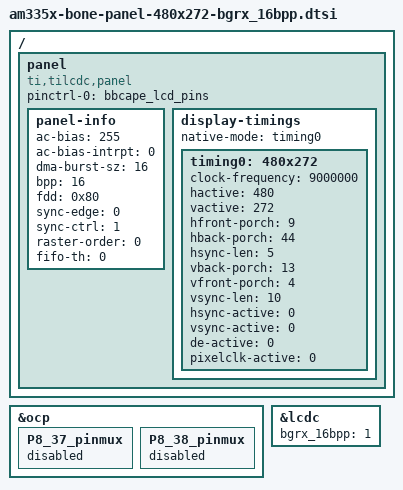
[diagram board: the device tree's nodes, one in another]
/*
 * Copyright (C) 2012 Texas Instruments Incorporated - http://www.ti.com/
 *
 * This program is free software; you can redistribute it and/or modify
 * it under the terms of the GNU General Public License version 2 as
 * published by the Free Software Foundation.
 */

&ocp {
	P8_37_pinmux {
		status = "disabled";
	};
	P8_38_pinmux {
		status = "disabled";
	};
};

&lcdc {
	bgrx_16bpp = <1>;
	status = "okay";
};

/ {
	panel {
		status = "okay";
		compatible = "ti,tilcdc,panel";
		pinctrl-names = "default";
		pinctrl-0 = <&bbcape_lcd_pins>;
		panel-info {
			ac-bias           = <255>;
			ac-bias-intrpt    = <0>;
			dma-burst-sz      = <16>;
			bpp               = <16>;
			fdd               = <0x80>;
			sync-edge         = <0>;
			sync-ctrl         = <1>;
			raster-order      = <0>;
			fifo-th           = <0>;
		};
		display-timings {
			native-mode = <&timing0>;
			timing0: 480x272 {
				clock-frequency = <9000000>;
				hactive = <480>;
				vactive = <272>;
				hfront-porch = <9>;
				hback-porch = <44>;
				hsync-len = <5>;
				vback-porch = <13>;
				vfront-porch = <4>;
				vsync-len = <10>;
				hsync-active = <0>;
				vsync-active = <0>;
				de-active = <0>;
				pixelclk-active = <0>;
			};
		};
	};
};
